# G32R502 register map
Vendor: Geehy Semiconductor Co., Ltd.; Series: G32R5; File version: 1.0
CPU: CM52 r0p1, little endian, MPU, FPU, DSP, VTOR, 4 interrupt priority bits
Registers are 32-bit, read-write, reset 0x0 unless marked. A register's access mark holds for its fields unless they carry their own. Offsets are from the block's base; [hi:lo] are bit positions.

## UARTA — Universal Asynchronous Transceiver
Base 0x40000800
Same registers: UARTB 0x40000C00, UARTC 0x40001000
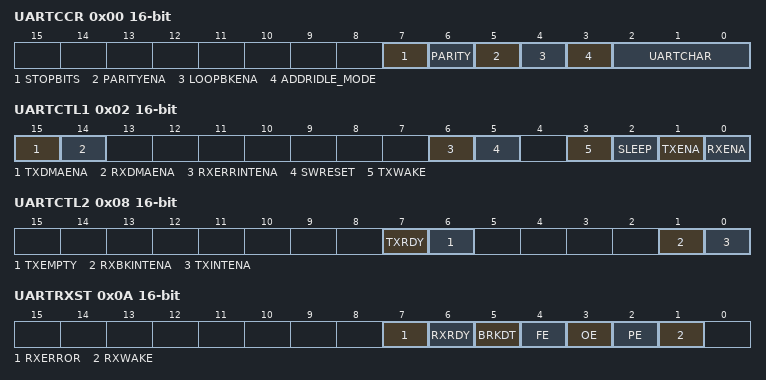
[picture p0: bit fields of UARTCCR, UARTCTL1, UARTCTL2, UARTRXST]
0x00 UARTCCR 16-bit — Communications control register
  [7] STOPBITS — UART number of stop bits
  [6] PARITY — UART parity odd/even selection
  [5] PARITYENA — UART parity enable
  [4] LOOPBKENA — Loop Back test mode enable
  [3] ADDRIDLE_MODE — UART multiprocessor mode control bit
  [2:0] UARTCHAR — Character-length control bits 2-0
0x02 UARTCTL1 16-bit — Control register 1
  [15] TXDMAENA — UART transmit DMA enable
  [14] RXDMAENA — UART receive DMA enable
  [6] RXERRINTENA — UART receive error interrupt enable
  [5] SWRESET — UART software reset (active low)
  [3] TXWAKE — UART transmitter wake-up method select
  [2] SLEEP — UART sleep
  [1] TXENA — UART transmitter enable
  [0] RXENA — UART receiver enable
0x04 UARTHBAUD 16-bit — Baud rate (high) register
  [7:0] BAUD — UART 16-bit baud selection Registers UARTHBAUD (MSbyte)
0x06 UARTLBAUD 16-bit — Baud rate (low) register
  [7:0] BAUD — See UARTHBAUD Detailed Description
0x08 UARTCTL2 16-bit — Control register 2
  [7] TXRDY — Transmitter buffer register ready flag
  [6] TXEMPTY — Transmitter empty flag
  [1] RXBKINTENA — Receiver-buffer/break interrupt enable
  [0] TXINTENA — UARTTXBUF-register interrupt enable
0x0A UARTRXST 16-bit — Receive status register
  [7] RXERROR — UART receiver error flag
  [6] RXRDY — UART receiver-ready flag
  [5] BRKDT — UART break-detect flag
  [4] FE — UART framing-error flag
  [3] OE — UART overrun-error flag
  [2] PE — UART parity-error flag
  [1] RXWAKE — Receiver wake-up-detect flag
0x0C UARTRXEMU 16-bit — Receive emulation buffer register
  [7:0] ERXDT — Receive emulation buffer data
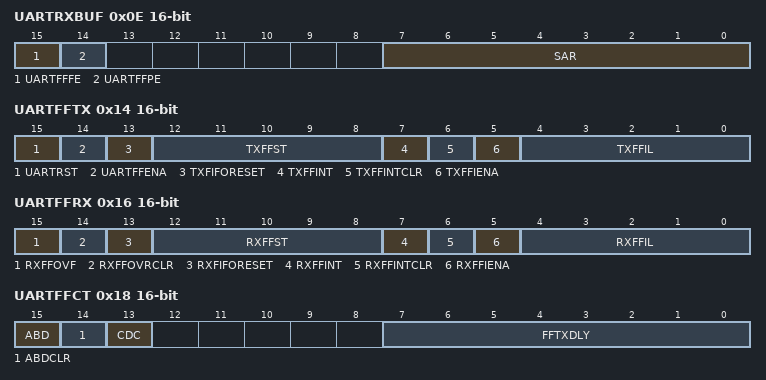
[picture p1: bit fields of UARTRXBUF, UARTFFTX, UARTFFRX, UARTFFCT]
0x0E UARTRXBUF 16-bit — Receive data buffer
  [15] UARTFFFE — UARTFFFE. UART FIFO Framing error flag bit
  [14] UARTFFPE — UARTFFPE. UART FIFO parity error flag bit
  [7:0] SAR — Receive Character bits
0x12 UARTTXBUF 16-bit — Transmit data buffer
  [7:0] TXDT
0x14 UARTFFTX 16-bit — FIFO transmit register
  [15] UARTRST — UART Reset
  [14] UARTFFENA — UART FIFO enable
  [13] TXFIFORESET — Transmit FIFO reset
  [12:8] TXFFST — FIFO status
  [7] TXFFINT — Transmit FIFO interrupt
  [6] TXFFINTCLR — Transmit FIFO clear
  [5] TXFFIENA — Transmit FIFO interrrupt enable
  [4:0] TXFFIL — TXFFIL4-0 Transmit FIFO interrupt level bits
0x16 UARTFFRX 16-bit — FIFO receive register
  [15] RXFFOVF — Receive FIFO overflow
  [14] RXFFOVRCLR — RXFFOVF clear
  [13] RXFIFORESET — Receive FIFO reset
  [12:8] RXFFST — FIFO status
  [7] RXFFINT — Receive FIFO interrupt
  [6] RXFFINTCLR — Receive FIFO interrupt clear
  [5] RXFFIENA — Receive FIFO interrupt enable
  [4:0] RXFFIL — Receive FIFO interrupt level bits
0x18 UARTFFCT 16-bit — FIFO control register
  [15] ABD — Auto-baud detect (ABD) bit
  [14] ABDCLR — ABD-clear bit
  [13] CDC — CDC calibrate A-detect bit
  [7:0] FFTXDLY — FIFO transfer delay
0x1E UARTPRI 16-bit — UART priority control
  [4:3] FREESOFT — These bits determine what occurs when an emulation suspend event

## GPIODATA_READ — GPIO DATA Read Registers
Base 0x40030900
0x00 GPADAT_R — GPIO A Data Read Register
  [31:0] DATA — Returns the contents of what was written to the GPADAT register on a read, write to this register has no effect
0x04 GPBDAT_R — GPIO B Data Read Register
  [31:0] DATA — Returns the contents of what was written to the GPBDAT register on a read, write to this register has no effect
0x1C GPHDAT_R — GPIO H Data Read Register
  [31:0] DATA — Returns the contents of what was written to the GPHDAT register on a read, write to this register has no effect
